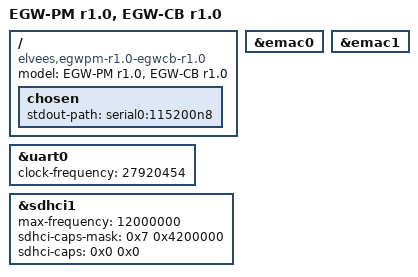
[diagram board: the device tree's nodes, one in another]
// SPDX-License-Identifier: GPL-2.0+
/*
 * Copyright 2021 RnD Center "ELVEES", JSC
 */

/dts-v1/;

#include <dt-bindings/gpio/gpio.h>
#include <dt-bindings/interrupt-controller/irq.h>

#include "mcom03-egwpm-r1.0.dtsi"

/ {
	model = "EGW-PM r1.0, EGW-CB r1.0";
	compatible = "elvees,egwpm-r1.0-egwcb-r1.0",
		     "elvees,egwpm-egwcb",
		     "elvees,egwcb-r1.0",
		     "elvees,egwcb",
		     "elvees,egwpm-r1.0",
		     "elvees,egwpm",
		     "elvees,mcom03";

	chosen {
		stdout-path = "serial0:115200n8";
	};
};

/* Connected to USB Type-C through CP2105 */
&uart0 {
	status = "okay";
	clock-frequency = <27920454>;
};

/* Connected to MicroSD card */
&sdhci1 {
	status = "okay";

	/* Unstable at 25 MHz on NGFW CB */
	max-frequency = <12000000>;

	/* Disable High Speed support
	 * Disable 1.8V support
	 * Disable SDR50, SDR104 and DDR50 support
	 */
	sdhci-caps-mask = <0x7 0x4200000>;
	sdhci-caps = <0x0 0x0>;
};

/* Connected to XP2 */
&emac0 {
	status = "okay";
};

/* Connected to XP3 */
&emac1 {
	status = "okay";
};
